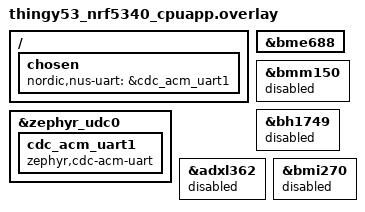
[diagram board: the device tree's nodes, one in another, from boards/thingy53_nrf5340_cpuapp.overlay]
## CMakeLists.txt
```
#
# Copyright (c) 2018 Nordic Semiconductor
#
# SPDX-License-Identifier: LicenseRef-Nordic-5-Clause
#
cmake_minimum_required(VERSION 3.20.0)

find_package(Zephyr REQUIRED HINTS $ENV{ZEPHYR_BASE})
project(NONE)

# NORDIC SDK APP START
target_sources(app PRIVATE
  src/main.c
)

# NORDIC SDK APP END
```

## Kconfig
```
#
# Copyright (c) 2018 Nordic Semiconductor
#
# SPDX-License-Identifier: LicenseRef-Nordic-5-Clause
#

source "Kconfig.zephyr"

menu "Nordic UART BLE GATT service sample"

config BT_NUS_THREAD_STACK_SIZE
	int "Thread stack size"
	default 1024
	help
	  Stack size used in each of the two threads

config BT_NUS_UART_BUFFER_SIZE
	int "UART payload buffer element size"
	default 40
	help
	  Size of the payload buffer in each RX and TX FIFO element

config BT_NUS_SECURITY_ENABLED
	bool "Security"
	default y
	select BT_SMP
	help
	  Enable Bluetooth LE security for the UART service

config BT_NUS_UART_RX_WAIT_TIME
	int "Timeout for UART RX complete event"
	default 50000
	help
	  Wait for RX complete event time in microseconds

config SETTINGS
	default y

config ZMS
	default y if (SOC_FLASH_NRF_RRAM || SOC_FLASH_NRF_MRAM)

config NVS
	default y if !(SOC_FLASH_NRF_RRAM || SOC_FLASH_NRF_MRAM)

endmenu
```

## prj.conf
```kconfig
#
# Copyright (c) 2018 Nordic Semiconductor
#
# SPDX-License-Identifier: LicenseRef-Nordic-5-Clause
#

# Enable the UART driver
CONFIG_UART_ASYNC_API=y
CONFIG_NRFX_UARTE=y
CONFIG_SERIAL=y

CONFIG_GPIO=y

# Make sure printk is printing to the UART console
CONFIG_CONSOLE=y
CONFIG_UART_CONSOLE=y

CONFIG_HEAP_MEM_POOL_SIZE=2048

CONFIG_BT=y
CONFIG_BT_PERIPHERAL=y
CONFIG_BT_DEVICE_NAME="Thingy53_mLRS"
CONFIG_BT_MAX_CONN=1
CONFIG_BT_MAX_PAIRED=1

# Enable the NUS service
CONFIG_BT_NUS=y

# Enable bonding
CONFIG_BT_SETTINGS=y
CONFIG_FLASH=y
CONFIG_FLASH_PAGE_LAYOUT=y
CONFIG_FLASH_MAP=y

# Enable DK LED and Buttons library
CONFIG_DK_LIBRARY=y

CONFIG_SYSTEM_WORKQUEUE_STACK_SIZE=2048
# Config logger
CONFIG_LOG=y
CONFIG_USE_SEGGER_RTT=y
CONFIG_LOG_BACKEND_RTT=y
CONFIG_LOG_BACKEND_UART=n
CONFIG_LOG_PRINTK=n

CONFIG_ASSERT=y

# Thingy sensor bridge
CONFIG_BT_NUS_SECURITY_ENABLED=n
CONFIG_SENSOR=y
CONFIG_BME680=y
CONFIG_MAIN_STACK_SIZE=4096
```

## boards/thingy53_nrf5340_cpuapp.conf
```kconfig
#
# Copyright (c) 2021 Nordic Semiconductor ASA
#
# SPDX-License-Identifier: LicenseRef-Nordic-5-Clause
#
################################################################################
# Application overlay - Thingy:53 DFU

CONFIG_NCS_SAMPLE_MCUMGR_BT_OTA_DFU=y

CONFIG_SYSTEM_WORKQUEUE_STACK_SIZE=4096

################################################################################
# Configure USB CDC ACM

CONFIG_USB_DEVICE_PRODUCT="Thingy:53 Nordic UART Service sample"
CONFIG_USB_DEVICE_PID=0x530E
CONFIG_USB_COMPOSITE_DEVICE=y

# Enable back logging over UART as this sample config uses only RTT by default
CONFIG_LOG_BACKEND_UART=y

CONFIG_UART_ASYNC_ADAPTER=y
CONFIG_UART_INTERRUPT_DRIVEN=y

# Disable the UARTE enabled in default project configuration
CONFIG_UART_NRFX=n
```

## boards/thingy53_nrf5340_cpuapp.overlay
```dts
/*
 * Copyright (c) 2021 Nordic Semiconductor ASA
 *
 * SPDX-License-Identifier: LicenseRef-Nordic-5-Clause
 */

/ {
	chosen {
		nordic,nus-uart = &cdc_acm_uart1;
	};
};

&zephyr_udc0 {
	cdc_acm_uart1: cdc_acm_uart1 {
		compatible = "zephyr,cdc-acm-uart";
	};
};

&bme688 { status = "okay"; };
&bmm150 { status = "disabled"; };
&bh1749 { status = "disabled"; };
&adxl362 { status = "disabled"; };
&bmi270 { status = "disabled"; };
```

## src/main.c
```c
/* Thingy:53 environmental measurements over Nordic UART Service.
 * SPDX-License-Identifier: MIT
 */
#include <zephyr/kernel.h>
#include <zephyr/device.h>
#include <zephyr/devicetree.h>
#include <zephyr/drivers/sensor.h>
#include <zephyr/bluetooth/bluetooth.h>
#include <zephyr/bluetooth/conn.h>
#include <zephyr/bluetooth/gatt.h>
#include <zephyr/settings/settings.h>
#include <zephyr/sys/atomic.h>
#include <zephyr/logging/log.h>
#include <bluetooth/services/nus.h>
#include <dk_buttons_and_leds.h>
#include <errno.h>
#include <string.h>
#include "sensor_text.h"

LOG_MODULE_REGISTER(thingy_bridge, LOG_LEVEL_INF);
static const struct device *env = DEVICE_DT_GET(DT_NODELABEL(bme688));
static struct bt_conn *peer;
K_MUTEX_DEFINE(peer_lock);
static atomic_t subscribed;
static struct k_work_delayable adv_work;
static const struct bt_data ad[] = {
    BT_DATA_BYTES(BT_DATA_FLAGS, BT_LE_AD_GENERAL | BT_LE_AD_NO_BREDR),
    BT_DATA_BYTES(BT_DATA_UUID128_ALL, BT_UUID_NUS_VAL),
};
static const struct bt_data sd[] = {
    BT_DATA(BT_DATA_NAME_COMPLETE, CONFIG_BT_DEVICE_NAME,
            sizeof(CONFIG_BT_DEVICE_NAME) - 1),
};

static void advertise(struct k_work *work)
{
    ARG_UNUSED(work);
    int err = bt_le_adv_start(BT_LE_ADV_CONN_FAST_2, ad, ARRAY_SIZE(ad),
                             sd, ARRAY_SIZE(sd));
    if (err && err != -EALREADY) {
        LOG_WRN("Advertising: %d; retry", err);
        k_work_reschedule(&adv_work, K_SECONDS(1));
    }
}
static void connected(struct bt_conn *conn, uint8_t err)
{
    if (err) {
        LOG_WRN("Connect failed: %u", err);
        k_work_reschedule(&adv_work, K_SECONDS(1));
        return;
    }
    k_mutex_lock(&peer_lock, K_FOREVER);
    peer = bt_conn_ref(conn);
    atomic_clear(&subscribed);
    k_mutex_unlock(&peer_lock);
    dk_set_led_on(DK_LED2);
    LOG_INF("BLE connected; enable NUS TX notifications");
}
static void disconnected(struct bt_conn *conn, uint8_t reason)
{
    struct bt_conn *old = NULL;
    k_mutex_lock(&peer_lock, K_FOREVER);
    if (peer == conn) {
        old = peer;
        peer = NULL;
        atomic_clear(&subscribed);
    }
    k_mutex_unlock(&peer_lock);
    if (old) { bt_conn_unref(old); }
    dk_set_led_off(DK_LED2);
    LOG_INF("BLE disconnected: %u", reason);
}
static void recycled(void)
{
    /* A fresh connection slot is available only after the final unref. */
    k_work_reschedule(&adv_work, K_NO_WAIT);
}
BT_CONN_CB_DEFINE(callbacks) = {
    .connected = connected, .disconnected = disconnected, .recycled = recycled,
};
static void send_enabled(enum bt_nus_send_status status)
{
    atomic_set(&subscribed, status == BT_NUS_SEND_STATUS_ENABLED);
}
static struct bt_nus_cb nus_callbacks = { .send_enabled = send_enabled };

static void send_line(const char *text)
{
    struct bt_conn *conn = NULL;
    k_mutex_lock(&peer_lock, K_FOREVER);
    if (peer && atomic_get(&subscribed)) { conn = bt_conn_ref(peer); }
    k_mutex_unlock(&peer_lock);
    if (!conn) { return; }

    /* 20-byte pieces also work with the default ATT MTU of 23.
     * Each record starts AND ends with LF, so a partial previous record
     * cannot be joined to the next record after a failed send.
     */
    size_t length = strlen(text);
    for (size_t offset = 0; offset < length;) {
        uint16_t count = (uint16_t)MIN(length - offset, 20U);
        int err = bt_nus_send(conn, (const uint8_t *)text + offset, count);
        if (err) {
            LOG_WRN("NUS send: %d; discard record", err);
            break;
        }
        offset += count;
        k_sleep(K_MSEC(10));
    }
    bt_conn_unref(conn);
}

static int64_t micro_value(const struct sensor_value *v)
{
    return (int64_t)v->val1 * 1000000 + v->val2;
}
int main(void)
{
    int err = dk_leds_init();
    if (err) { LOG_WRN("LED init: %d", err); }
    k_work_init_delayable(&adv_work, advertise);
    err = bt_enable(NULL);
    if (err) { LOG_ERR("Bluetooth init: %d", err); return 0; }
    if (IS_ENABLED(CONFIG_SETTINGS)) {
        err = settings_load();
        if (err) { LOG_WRN("Settings: %d", err); }
    }
    err = bt_nus_init(&nus_callbacks);
    if (err) { LOG_ERR("NUS init: %d", err); return 0; }
    k_work_reschedule(&adv_work, K_NO_WAIT);
    LOG_INF("Thingy53_mLRS sensor bridge started");

    for (;;) {
        int64_t next_sample = k_uptime_get() + 5000;
        struct sensor_value t, h, p;
        char line[80];
        err = device_is_ready(env) ? sensor_sample_fetch(env) : -ENODEV;
        if (!err) { err = sensor_channel_get(env, SENSOR_CHAN_AMBIENT_TEMP, &t); }
        if (!err) { err = sensor_channel_get(env, SENSOR_CHAN_HUMIDITY, &h); }
        if (!err) { err = sensor_channel_get(env, SENSOR_CHAN_PRESS, &p); }
        if (err) {
            dk_set_led_on(DK_LED1);
            snprintf(line, sizeof(line), "\nERR:BME688:%d\n", err);
            LOG_ERR("BME688 read: %d", err);
        } else {
            dk_set_led_off(DK_LED1);
            /* Zephyr pressure is kPa; text output is absolute hPa. */
            int n = sensor_text(line, sizeof(line), micro_value(&t),
                                micro_value(&h), micro_value(&p));
            if (n < 0 || (size_t)n >= sizeof(line)) {
                LOG_ERR("Text buffer overflow");
                k_sleep(K_SECONDS(5));
                continue;
            }
            LOG_INF("%s", line + 1);
        }
        send_line(line);
        dk_set_led_on(DK_LED3);
        k_sleep(K_MSEC(50));
        dk_set_led_off(DK_LED3);
        int64_t wait_ms = next_sample - k_uptime_get();
        if (wait_ms > 0) { k_sleep(K_MSEC(wait_ms)); }
    }
}
```

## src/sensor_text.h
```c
/* SPDX-License-Identifier: MIT */
#ifndef SENSOR_TEXT_H
#define SENSOR_TEXT_H
#include <stdint.h>
#include <stdio.h>
/* Inputs: micro-degrees C, micro-percent RH, micro-kPa. */
static inline int sensor_text(char *out, size_t size, int64_t t, int64_t h, int64_t p)
{
    /* Round temperature to tenths, preserving -0.x. */
    int64_t temp10 = t >= 0 ? (t + 50000) / 100000 : -((-t + 50000) / 100000);
    int64_t abs10 = temp10 < 0 ? -temp10 : temp10;
    long rh = (long)((h + 500000) / 1000000);
    long hpa = (long)((p + 50000) / 100000);
    return snprintf(out, size, "\nT:%s%ld.%ldC H:%ld%% P:%ldhPa\n",
                    temp10 < 0 ? "-" : "", (long)(abs10 / 10),
                    (long)(abs10 % 10), rh, hpa);
}
#endif
```
